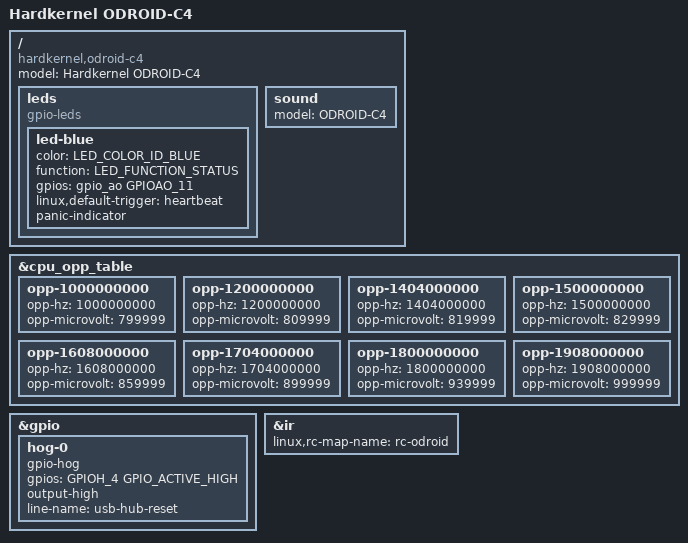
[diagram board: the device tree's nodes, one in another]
// SPDX-License-Identifier: (GPL-2.0+ OR MIT)
/*
 * Copyright (c) 2020 Dongjin Kim <tobetter@gmail.com>
 */

/dts-v1/;

#include "meson-sm1-odroid.dtsi"

/ {
	compatible = "hardkernel,odroid-c4", "amlogic,sm1";
	model = "Hardkernel ODROID-C4";

	leds {
		compatible = "gpio-leds";

		led-blue {
			color = <LED_COLOR_ID_BLUE>;
			function = LED_FUNCTION_STATUS;
			gpios = <&gpio_ao GPIOAO_11 GPIO_ACTIVE_HIGH>;
			linux,default-trigger = "heartbeat";
			panic-indicator;
		};
	};

	sound {
		model = "ODROID-C4";
	};
};

&cpu_opp_table {
	opp-1000000000 {
		opp-hz = /bits/ 64 <1000000000>;
		opp-microvolt = <799999>;
	};

	opp-1200000000 {
		opp-hz = /bits/ 64 <1200000000>;
		opp-microvolt = <809999>;
	};

	opp-1404000000 {
		opp-hz = /bits/ 64 <1404000000>;
		opp-microvolt = <819999>;
	};

	opp-1500000000 {
		opp-hz = /bits/ 64 <1500000000>;
		opp-microvolt = <829999>;
	};

	opp-1608000000 {
		opp-hz = /bits/ 64 <1608000000>;
		opp-microvolt = <859999>;
	};

	opp-1704000000 {
		opp-hz = /bits/ 64 <1704000000>;
		opp-microvolt = <899999>;
	};

	opp-1800000000 {
		opp-hz = /bits/ 64 <1800000000>;
		opp-microvolt = <939999>;
	};

	opp-1908000000 {
		opp-hz = /bits/ 64 <1908000000>;
		opp-microvolt = <999999>;
	};
};

&gpio {
	/*
	 * WARNING: The USB Hub on the Odroid-C4 needs a reset signal
	 * to be turned high in order to be detected by the USB Controller
	 * This signal should be handled by a USB specific power sequence
	 * in order to reset the Hub when USB bus is powered down.
	 */
	hog-0 {
		gpio-hog;
		gpios = <GPIOH_4 GPIO_ACTIVE_HIGH>;
		output-high;
		line-name = "usb-hub-reset";
	};
};

&ir {
	linux,rc-map-name = "rc-odroid";
};
